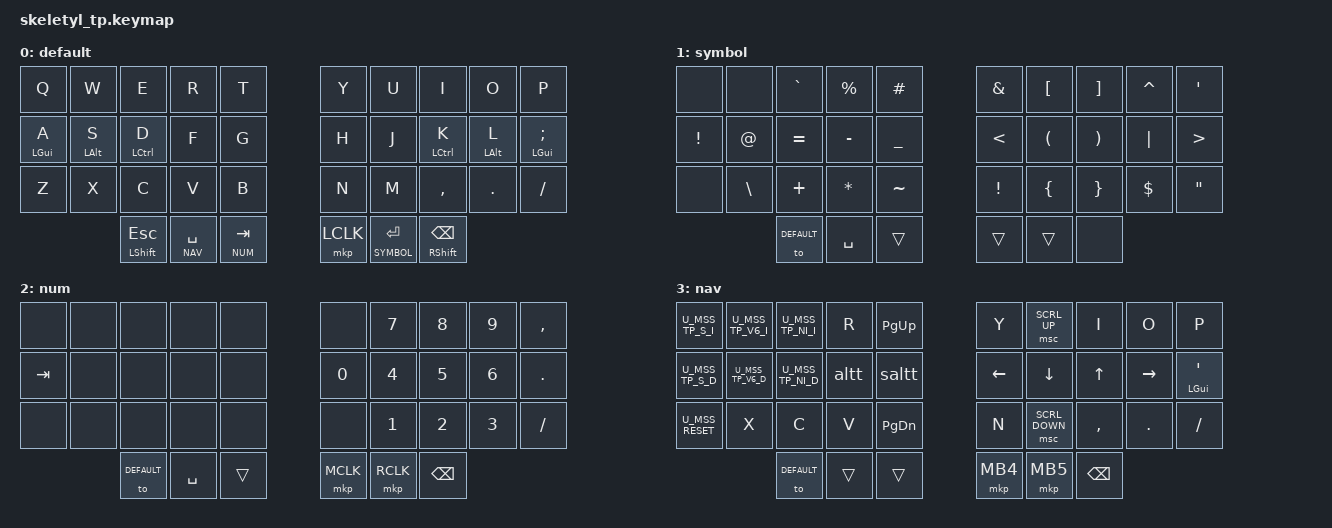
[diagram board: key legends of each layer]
#include <behaviors.dtsi>
#include <dt-bindings/zmk/keys.h>
#include <dt-bindings/zmk/bt.h>
#include <dt-bindings/zmk/outputs.h>

// Modified keymap based on personal experience, with some improvements based on Miryoku layout.

#define DEFAULT 0
#define SYMBOL  1
#define NUM     2
#define NAV     3

/*
 * Defines to enable/disable features
 *
 * These defines allow us to conditionally enable and disable parts of the keymap config.
 *
 * For example, if we decide to build the firmware without the mouse features, we can
 * disable all the config options that rely on those forks and modules without having
 * to edit the entire keymap file manually every time.
 */

#define HAS_MOUSE_KEYS
#define HAS_MOUSE_TP

#ifdef HAS_MOUSE_KEYS
  #include <dt-bindings/zmk/mouse.h>
  #include <behaviors/mouse_keys.dtsi>
#endif  // HAS_MOUSE_KEYS

#ifdef HAS_MOUSE_TP
  // We store the trackpoint settings in a separate file
  // to make organization a little easier.
  #include "include/mouse_tp.dtsi"
#endif  // HAS_MOUSE_TP



// Adjust layer keys based on enabled features.
//
// This prevents build errors when we build the firmware
// without the mouse keys PR or the TP module.
#ifdef HAS_MOUSE_KEYS
  #define U_THUMB_INNER &mo MOUSE_KEYS
#else
  #define U_THUMB_INNER &none
#endif  // HAS_MOUSE_KEYS

#ifdef HAS_MOUSE_TP
  #define U_TOG_TP_SET &tog MOUSE_TP_SET
#else
  #define U_TOG_TP_SET &none
#endif  // HAS_MOUSE_TP




/ {
    behaviors {
        hml: homerow_mods_left_no_delay {
             compatible = "zmk,behavior-hold-tap";
             flavor = "balanced";
             tapping-term-ms = <280>;
             #binding-cells = <2>;
             quick-tap-ms = <175>;                // repeat on tap-into-hold
             require-prior-idle-ms = <150>;
             bindings = <&kp>, <&kp>;
             hold-trigger-key-positions = <5 6 7 8 9 15 16 17 18 19 25 26 27 28 29 33 34 35>;
             hold-trigger-on-release;             // delay positional check until key-release
        };
        hmr: homerow_mods_rightno_delay {
             compatible = "zmk,behavior-hold-tap";
             flavor = "balanced";
             tapping-term-ms = <280>;
             #binding-cells = <2>;
             require-prior-idle-ms = <150>;
             quick-tap-ms = <175>;                // repeat on tap-into-hold
             bindings = <&kp>, <&kp>;
             hold-trigger-key-positions = <0 1 2 3 4 10 11 12 13 14 20 21 22 23 24 30 31 32>;
             hold-trigger-on-release;             // delay positional check until key-release
        };
        sd: shift_dance {
            compatible = "zmk,behavior-tap-dance";
            #binding-cells = <0>;
            tapping-term-ms = <200>;
            bindings = <&kp LSHIFT>, <&kp CAPS>;
        };
    };

    combos {
        compatible = "zmk,combos";
    };
    macros {
       def: def {
          compatible = "zmk,behavior-macro-one-param";
          wait-ms = <0>;
          tap-ms = <0>;
          #binding-cells = <1>;
          bindings
              = <&macro_param_1to1>
              , <&macro_tap &kp MACRO_PLACEHOLDER>
              , <&macro_tap &to DEFAULT>
              ;
       };
       altt: altt {
          compatible = "zmk,behavior-macro";
          wait-ms = <0>;
          tap-ms = <0>;
          #binding-cells = <0>;
          bindings
                = <&macro_press &kp LGUI>
                , <&macro_tap &kp TAB>
                , <&macro_release &kp LGUI>
                ;
                        
       };
       saltt: saltt {
          compatible = "zmk,behavior-macro";
          wait-ms = <0>;
          tap-ms = <0>;
          #binding-cells = <0>;
          bindings
                = <&macro_press &kp LGUI>
                , <&macro_press &kp RSHIFT>
                , <&macro_tap &kp TAB>
                , <&macro_release &kp RSHIFT>
                , <&macro_release &kp LGUI>
                ;
                        
       };
       tevil: tevil {
          compatible = "zmk,behavior-macro";
          wait-ms = <0>;
          tap-ms = <0>;
          #binding-cells = <0>;
          bindings
                = <&macro_tap &kp SPACE>
                , <&macro_tap &kp BSPC>
                ;
                        
       };
    };

    keymap {
        compatible = "zmk,keymap";

        default {
            bindings = <
    &kp  Q        &kp  W         &kp  E         &kp  R           &kp T           &kp Y       &kp  U              &kp  I             &kp  O         &kp P
    &hml LGUI A &hml LALT S  &hml LCTRL D &kp F            &kp G           &kp H       &kp  J              &hmr LCTRL K     &hmr LALT L  &hmr LGUI SEMI 
    &kp  Z        &kp  X         &kp C          &kp  V           &kp B           &kp N       &kp  M              &kp  COMMA         &kp  DOT       &kp FSLH
                                 &mt LSHIFT ESC    &lt NAV SPACE    &lt NUM TAB        &mkp LCLK   &lt SYMBOL  RET   &mt RSHIFT BSPC
            >;
        };

        symbol {
            bindings = <
    &none         &none     &kp GRAVE    &kp PRCNT      &kp HASH        &kp AMPS    &kp  LBKT    &kp  RBKT    &kp CARET    &kp SQT
    &kp EXCL      &kp AT    &kp EQUAL    &kp MINUS      &kp UNDER       &kp LT      &kp  LPAR    &kp  RPAR    &kp PIPE     &kp GT       
    &none         &kp BSLH  &kp PLUS     &kp STAR       &kp TILDE       &kp EXCL    &kp  LBRC    &kp  RBRC    &kp DLLR     &kp DQT
                            &to DEFAULT  &kp SPACE      &trans          &trans      &trans       &none
            >;
        };

        num {
            bindings = <
    &none     &none        &none        &none          &none            &none        &kp N7       &kp  N8      &kp N9         &kp COMMA
    &kp TAB   &none        &none        &none          &none            &kp  N0      &kp N4       &kp  N5      &kp N6         &kp DOT      
    &none     &none        &none        &none          &none            &none        &kp N1       &kp  N2      &kp N3         &kp FSLH
                           &to DEFAULT  &kp SPACE      &trans           &mkp MCLK    &mkp RCLK    &kp  BSPC
            >;
        };



        nav {
            bindings = <
    U_MSS_TP_S_I  U_MSS_TP_V6_I  U_MSS_TP_NI_I        &kp  R           &kp PG_UP       &kp Y       &msc  SCRL_UP      &kp  I       &kp  O       &kp P
    U_MSS_TP_S_D  U_MSS_TP_V6_D  U_MSS_TP_NI_D        &altt            &saltt          &kp LEFT    &kp   DOWN         &kp  UP      &kp  RIGHT   &hmr LGUI SQT
    U_MSS_RESET   &kp  X         &kp C                &kp  V           &kp PG_DN       &kp N       &msc  SCRL_DOWN    &kp  COMMA   &kp  DOT     &kp FSLH
                                 &to DEFAULT          &trans           &trans          &mkp MB4    &mkp  MB5          &kp BSPC
            >;
        };
    };
};
